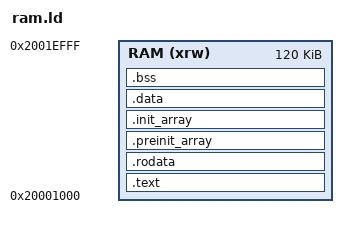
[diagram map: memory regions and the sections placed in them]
ENTRY(app)

MEMORY {
    RAM (xrw) : ORIGIN = 0x20001000, LENGTH = 120K /* fits in F407 */
}

SECTIONS {
  .text : {
    . = ALIGN(4);
    *(.start)          /* .start section (header) */
    *(.text)           /* .text sections (code) */
    *(.text*)          /* .text* sections (code) */
    KEEP (*(.init))
    KEEP (*(.fini))
    . = ALIGN(4);
    _etext = .;        /* define a global symbols at end of code */
  } >RAM

  .rodata : {
    . = ALIGN(4);
    *(.rodata)         /* .rodata sections (constants, strings, etc.) */
    *(.rodata*)        /* .rodata* sections (constants, strings, etc.) */
    . = ALIGN(4);
  } >RAM

  .preinit_array : {
    . = ALIGN(4);
    PROVIDE_HIDDEN (__preinit_array_start = .);
    KEEP (*(.preinit_array*))
    PROVIDE_HIDDEN (__preinit_array_end = .);
    . = ALIGN(4);
  } >RAM
  
  .init_array : {
    . = ALIGN(4);
    PROVIDE_HIDDEN (__init_array_start = .);
    KEEP (*(SORT(.init_array.*)))
    KEEP (*(.init_array*))
    PROVIDE_HIDDEN (__init_array_end = .);
    . = ALIGN(4);
  } >RAM
  
  .data : {
    . = ALIGN(4);
    _sdata = .;        /* create a global symbol at data start */
    *(.data)           /* .data sections */
    *(.data*)          /* .data* sections */
    . = ALIGN(4);
    _edata = .;        /* define a global symbol at data end */
  } >RAM
  
  . = ALIGN(4);
  .bss : {
    _sbss = .;         /* define a global symbol at bss start */
    *(.bss)
    *(.bss*)
    *(COMMON)
    . = ALIGN(4);
    _ebss = .;         /* define a global symbol at bss end */
  } >RAM

  /DISCARD/ : {
    libc.a ( * )
    libm.a ( * )
    libgcc.a ( * )
  }

  .ARM.attributes 0 : { *(.ARM.attributes) }
}
